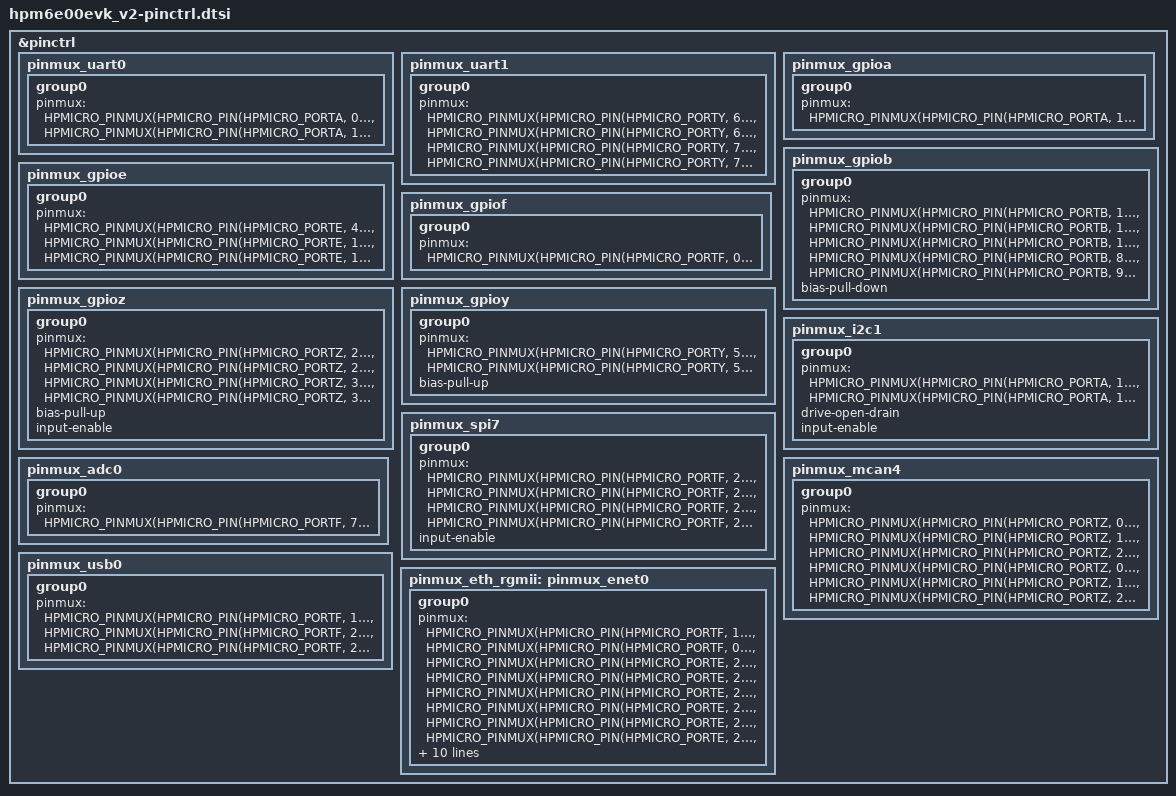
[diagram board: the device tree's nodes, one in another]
/*
 * Copyright 2025 HPMicro
 * SPDX-License-Identifier: Apache-2.0
 */

#include "dt-bindings/pinctrl/hpmicro-pinctrl-common.h"

&pinctrl {
	pinmux_uart0: pinmux_uart0 {
		group0 {
			pinmux = <HPMICRO_PINMUX(HPMICRO_PIN(HPMICRO_PORTA, 0), IOC_TYPE_IOC, 0, 2)>,
					 <HPMICRO_PINMUX(HPMICRO_PIN(HPMICRO_PORTA, 1), IOC_TYPE_IOC, 0, 2)>;
		};
	};
	pinmux_uart1: pinmux_uart1 {
		group0 {
			pinmux = <HPMICRO_PINMUX(HPMICRO_PIN(HPMICRO_PORTY, 6), IOC_TYPE_IOC, 0, 2)>,
					 <HPMICRO_PINMUX(HPMICRO_PIN(HPMICRO_PORTY, 6), IOC_TYPE_IOC, 0, 2)>,
					 <HPMICRO_PINMUX(HPMICRO_PIN(HPMICRO_PORTY, 7), IOC_TYPE_PIOC, 0, 3)>,
					 <HPMICRO_PINMUX(HPMICRO_PIN(HPMICRO_PORTY, 7), IOC_TYPE_PIOC, 0, 3)>;
		};
	};

	pinmux_gpioa: pinmux_gpioa {
		group0 {
			pinmux = <HPMICRO_PINMUX(HPMICRO_PIN(HPMICRO_PORTA, 14), IOC_TYPE_IOC, 0, 0)>;
		};
	};

	pinmux_gpiob: pinmux_gpiob {
		group0 {
			pinmux = <HPMICRO_PINMUX(HPMICRO_PIN(HPMICRO_PORTB, 11), IOC_TYPE_IOC, 0, 0)>,
					 <HPMICRO_PINMUX(HPMICRO_PIN(HPMICRO_PORTB, 12), IOC_TYPE_IOC, 0, 0)>,
					 <HPMICRO_PINMUX(HPMICRO_PIN(HPMICRO_PORTB, 13), IOC_TYPE_IOC, 0, 0)>,
					 <HPMICRO_PINMUX(HPMICRO_PIN(HPMICRO_PORTB, 8), IOC_TYPE_IOC, 0, 0)>,
					 <HPMICRO_PINMUX(HPMICRO_PIN(HPMICRO_PORTB, 9), IOC_TYPE_IOC, 0, 0)>;
			bias-pull-down;
		};
	};

	pinmux_gpioe: pinmux_gpioe {
		group0 {
			pinmux = <HPMICRO_PINMUX(HPMICRO_PIN(HPMICRO_PORTE, 4), IOC_TYPE_IOC, 0, 0)>,
					 <HPMICRO_PINMUX(HPMICRO_PIN(HPMICRO_PORTE, 14), IOC_TYPE_IOC, 0, 0)>,
					 <HPMICRO_PINMUX(HPMICRO_PIN(HPMICRO_PORTE, 15), IOC_TYPE_IOC, 0, 0)>;
		};
	};

	pinmux_gpiof: pinmux_gpiof {
		group0 {
			pinmux = <HPMICRO_PINMUX(HPMICRO_PIN(HPMICRO_PORTF, 0), IOC_TYPE_IOC, 0, 0)>;
		};
	};

	pinmux_gpioz: pinmux_gpioz {
		group0 {
			pinmux = <HPMICRO_PINMUX(HPMICRO_PIN(HPMICRO_PORTZ, 2), IOC_TYPE_IOC, 0, 0)>,
					 <HPMICRO_PINMUX(HPMICRO_PIN(HPMICRO_PORTZ, 2), IOC_TYPE_BIOC, 0, 3)>,
					 <HPMICRO_PINMUX(HPMICRO_PIN(HPMICRO_PORTZ, 3), IOC_TYPE_IOC, 0, 0)>,
					 <HPMICRO_PINMUX(HPMICRO_PIN(HPMICRO_PORTZ, 3), IOC_TYPE_BIOC, 0, 3)>;
			bias-pull-up;
			input-enable;
		};
	};

	pinmux_gpioy: pinmux_gpioy {
		group0 {
			pinmux = <HPMICRO_PINMUX(HPMICRO_PIN(HPMICRO_PORTY, 5), IOC_TYPE_IOC, 0, 0)>,
					 <HPMICRO_PINMUX(HPMICRO_PIN(HPMICRO_PORTY, 5), IOC_TYPE_BIOC, 0, 3)>;
			bias-pull-up;
		};
	};

	pinmux_i2c1: pinmux_i2c1 {
		group0 {
			pinmux = <HPMICRO_PINMUX(HPMICRO_PIN(HPMICRO_PORTA, 12), IOC_TYPE_IOC, 0, 4)>,
					 <HPMICRO_PINMUX(HPMICRO_PIN(HPMICRO_PORTA, 13), IOC_TYPE_IOC, 0, 4)>;
					 drive-open-drain;
					 input-enable;
		};
	};

	pinmux_spi7: pinmux_spi7 {
		group0 {
			pinmux = <HPMICRO_PINMUX(HPMICRO_PIN(HPMICRO_PORTF, 27), IOC_TYPE_IOC, 0, 5)>,
					 <HPMICRO_PINMUX(HPMICRO_PIN(HPMICRO_PORTF, 28), IOC_TYPE_IOC, 0, 5)>,
					 <HPMICRO_PINMUX(HPMICRO_PIN(HPMICRO_PORTF, 29), IOC_TYPE_IOC, 0, 5)>,
					 <HPMICRO_PINMUX(HPMICRO_PIN(HPMICRO_PORTF, 26), IOC_TYPE_IOC, 0, 5)>;
					 input-enable;
		};
	};

	pinmux_adc0: pinmux_adc0 {
		group0 {
			pinmux = <HPMICRO_PINMUX(HPMICRO_PIN(HPMICRO_PORTF, 7), IOC_TYPE_IOC, 1, 0)>;
		};
	};

	pinmux_mcan4: pinmux_mcan4 {
		group0 {
			pinmux = <HPMICRO_PINMUX(HPMICRO_PIN(HPMICRO_PORTZ, 0), IOC_TYPE_IOC, 0, 7)>,
					 <HPMICRO_PINMUX(HPMICRO_PIN(HPMICRO_PORTZ, 1), IOC_TYPE_IOC, 0, 7)>,
					 <HPMICRO_PINMUX(HPMICRO_PIN(HPMICRO_PORTZ, 2), IOC_TYPE_IOC, 0, 7)>,
					 <HPMICRO_PINMUX(HPMICRO_PIN(HPMICRO_PORTZ, 0), IOC_TYPE_BIOC, 0, 3)>,
					 <HPMICRO_PINMUX(HPMICRO_PIN(HPMICRO_PORTZ, 1), IOC_TYPE_BIOC, 0, 3)>,
					 <HPMICRO_PINMUX(HPMICRO_PIN(HPMICRO_PORTZ, 2), IOC_TYPE_BIOC, 0, 3)>;
		};
	};

	pinmux_usb0: pinmux_usb0 {
		group0 {
			pinmux = <HPMICRO_PINMUX(HPMICRO_PIN(HPMICRO_PORTF, 19), IOC_TYPE_IOC, 0, 24)>,
					 <HPMICRO_PINMUX(HPMICRO_PIN(HPMICRO_PORTF, 22), IOC_TYPE_IOC, 0, 24)>,
					 <HPMICRO_PINMUX(HPMICRO_PIN(HPMICRO_PORTF, 23), IOC_TYPE_IOC, 0, 24)>;
		};
	};

	pinmux_eth_rgmii: pinmux_enet0 {
		group0 {
			pinmux = <HPMICRO_PINMUX(HPMICRO_PIN(HPMICRO_PORTF, 1), IOC_TYPE_IOC, 0, 18)>,
					 <HPMICRO_PINMUX(HPMICRO_PIN(HPMICRO_PORTF, 0), IOC_TYPE_IOC, 0, 18)>,
					 <HPMICRO_PINMUX(HPMICRO_PIN(HPMICRO_PORTE, 20), IOC_TYPE_IOC, 0, 18)>,
					 <HPMICRO_PINMUX(HPMICRO_PIN(HPMICRO_PORTE, 21), IOC_TYPE_IOC, 0, 18)>,
					 <HPMICRO_PINMUX(HPMICRO_PIN(HPMICRO_PORTE, 22), IOC_TYPE_IOC, 0, 18)>,
					 <HPMICRO_PINMUX(HPMICRO_PIN(HPMICRO_PORTE, 23), IOC_TYPE_IOC, 0, 18)>,
					 <HPMICRO_PINMUX(HPMICRO_PIN(HPMICRO_PORTE, 24), IOC_TYPE_IOC, 0, 18)>,
			         <HPMICRO_PINMUX(HPMICRO_PIN(HPMICRO_PORTE, 25), IOC_TYPE_IOC, 0, 18)>,
				     <HPMICRO_PINMUX(HPMICRO_PIN(HPMICRO_PORTE, 26), IOC_TYPE_IOC, 0, 18)>,
				     <HPMICRO_PINMUX(HPMICRO_PIN(HPMICRO_PORTE, 27), IOC_TYPE_IOC, 0, 18)>,
				     <HPMICRO_PINMUX(HPMICRO_PIN(HPMICRO_PORTE, 28), IOC_TYPE_IOC, 0, 18)>,
				     <HPMICRO_PINMUX(HPMICRO_PIN(HPMICRO_PORTE, 29), IOC_TYPE_IOC, 0, 18)>,
				     <HPMICRO_PINMUX(HPMICRO_PIN(HPMICRO_PORTE, 30), IOC_TYPE_IOC, 0, 18)>,
				     <HPMICRO_PINMUX(HPMICRO_PIN(HPMICRO_PORTE, 31), IOC_TYPE_IOC, 0, 18)>;
			input-schmitt-enable;
			slew-rate = "fast";
			slew-pd = "100M";
			drive-strength = "r011";
		};
	};
};
